# MCU_NAVSS0_UDMASS_RINGACC0_ISC_ISC register map
Vendor: Texas Instruments
Peripheral module from a debugger description file (folder am65x).
Registers are 32-bit, access not given, reset 0x0 unless marked. A register's access mark holds for its fields unless they carry their own. Offsets are as the file gives them; lines under a group give offsets from that group; [hi:lo] are bit positions; {n}, {i} and the like mark numbered series; 'fields as' and 'values as' point back to an identical list; <NAME> marks a mode.

## MCU_NAVSS0_UDMASS_RINGACC0_ISC_ISC
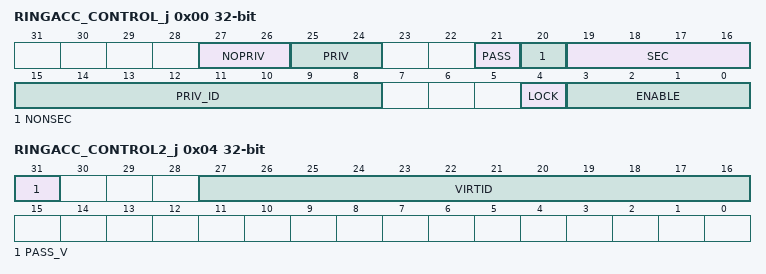
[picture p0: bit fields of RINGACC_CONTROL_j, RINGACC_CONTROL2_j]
0x00 RINGACC_CONTROL_j (reset mask 0xF3F001F) — The ISC a Region b Control Register defines the control fields for the ISC. Offset = 0h + (j * 20h); where j = 0h to 331h for NAVSS0_UDMASS_RINGACC0_ISC_ISC j = 0h to 11Dh for MCU_NAVSS0_UDMASS_RINGACC0_ISC_ISC
  [27:26] NOPRIV rw — Clear output priv attribute. If each bit is set then the outgoing priv bit is cleared. Has precedence over priv set bits.
  [25:24] PRIV rw — Set outgoing priv attribute. If each bit is set then the outgoing priv bit is set.
  [21] PASS rw — No privID replacement, pass through value.
  [20] NONSEC rw — Make outgoing non-secure. Has precedence over secure enable bits.
  [19:16] SEC rw — Make outgoing secure. A value of 0xA enables, others disable.
  [15:8] PRIV_ID rw
  [4] LOCK — Lock region. Once set the region values cannot be modified. (access RW1S)
  [3:0] ENABLE rw — Enable region. A value of 0xA enables, others disable.
0x04 RINGACC_CONTROL2_j rw — The ISC a Region b Control Register 2 defines the control fields for the ISC. Offset = 4h + (j * 20h); where j = 0h to 331h for NAVSS0_UDMASS_RINGACC0_ISC_ISC j = 0h to 11Dh for MCU_NAVSS0_UDMASS_RINGACC0_ISC_ISC
  [31] PASS_V — No virtID replacement, pass through value.
  [27:16] VIRTID
